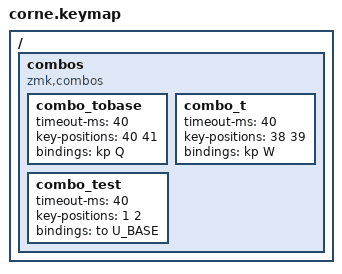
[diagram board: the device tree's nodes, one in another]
// Copyright 2021 Manna Harbour
// https://github.com/manna-harbour/miryoku

#include "../miryoku/custom_config.h"
#include "../miryoku/mapping/42/corne.h"
#include "../miryoku/miryoku.dtsi"

/ {
    combos {
        compatible = "zmk,combos";
        combo_tobase {
            timeout-ms = <40>;
            key-positions = <40 41>;
            bindings = <&kp Q>;
        };
    };
};
/ {
    combos {
        compatible = "zmk,combos";
        combo_t {
            timeout-ms = <40>;
            key-positions = <38 39>;
            bindings = <&kp W>;
        };
    };
};
/ {
    combos {
        compatible = "zmk,combos";
        combo_test {
            timeout-ms = <40>;
            key-positions = <1 2>;
            bindings = <&to U_BASE>;
        };
    };
};
